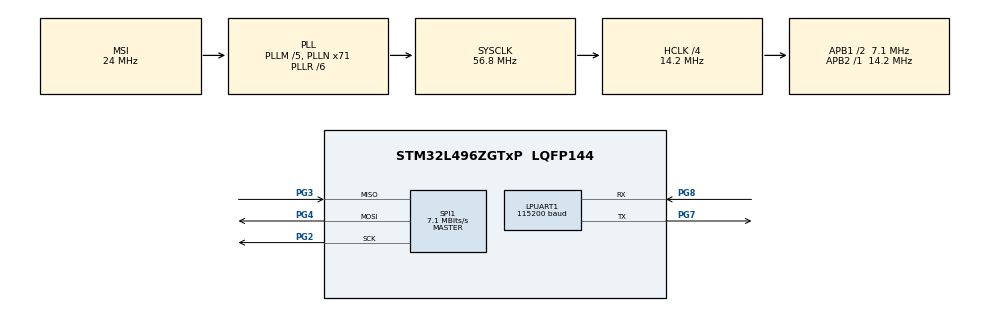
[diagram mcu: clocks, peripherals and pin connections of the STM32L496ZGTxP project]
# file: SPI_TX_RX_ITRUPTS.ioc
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LPUART1.BaudRate=115200
LPUART1.WordLength=UART_WORDLENGTH_8B
Mcu.Family=STM32L4
Mcu.Name=STM32L496ZGTxP
Mcu.Package=LQFP144
NVIC.LPUART1_IRQn=true\:0\:0\:false\:false\:true\:true\:true\:true
NVIC.PriorityGroup=NVIC_PRIORITYGROUP_4
NVIC.SPI1_IRQn=true\:0\:0\:false\:false\:true\:true\:true\:true
PG2.Mode=Full_Duplex_Master
PG2.Signal=SPI1_SCK
PG3.Mode=Full_Duplex_Master
PG3.Signal=SPI1_MISO
PG4.Mode=Full_Duplex_Master
PG4.Signal=SPI1_MOSI
PG7.Mode=Asynchronous
PG7.Signal=LPUART1_TX
PG8.Mode=Asynchronous
PG8.Signal=LPUART1_RX
ProjectManager.HeapSize=0x200
ProjectManager.StackSize=0x400
ProjectManager.TargetToolchain=STM32CubeIDE
RCC.48MHZClocksFreq_Value=24000000
RCC.ADCFreq_Value=48000000
RCC.AHBCLKDivider=RCC_SYSCLK_DIV4
RCC.AHBFreq_Value=14200000
RCC.APB1CLKDivider=RCC_HCLK_DIV2
RCC.APB1Freq_Value=7100000
RCC.APB1TimFreq_Value=14200000
RCC.APB2Freq_Value=14200000
RCC.APB2TimFreq_Value=14200000
RCC.CortexFreq_Value=14200000
RCC.HCLKFreq_Value=14200000
RCC.HSE_VALUE=8000000
RCC.HSI48_VALUE=48000000
RCC.HSI_VALUE=16000000
RCC.LSE_VALUE=32768
RCC.MSIClockRange=RCC_MSIRANGE_9
RCC.MSI_VALUE=24000000
RCC.PLLM=5
RCC.PLLMUL=RCC_PLL_MUL9
RCC.PLLN=71
RCC.PLLR=RCC_PLLR_DIV6
RCC.PLLSAI1N=20
RCC.PRESCALERUSB=RCC_USBCLKSOURCE_PLL_DIV1_5
RCC.SYSCLKFreq_VALUE=56800000
RCC.SYSCLKSource=RCC_SYSCLKSOURCE_PLLCLK
RCC.SYSCLKSourceVirtual=RCC_SYSCLKSOURCE_PLLCLK
RCC.USBFreq_Value=48000000
RCC.VCOOutputFreq_Value=340800000
SPI1.CLKPolarity=SPI_POLARITY_LOW
SPI1.CalculateBaudRate=7.1 MBits/s
SPI1.DataSize=SPI_DATASIZE_8BIT
SPI1.Direction=SPI_DIRECTION_2LINES
SPI1.Mode=SPI_MODE_MASTER
SPI1.VirtualType=VM_MASTER
board=NUCLEO-L496ZG-P

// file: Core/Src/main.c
/* USER CODE BEGIN Header */
/**
  ******************************************************************************
  * @file           : main.c
  * @brief          : Main program body
  ******************************************************************************
  * @attention
  *
  * Copyright (c) 2023 STMicroelectronics.
  * All rights reserved.
  *
  * This software is licensed under terms that can be found in the LICENSE file
  * in the root directory of this software component.
  * If no LICENSE file comes with this software, it is provided AS-IS.
  *
  ******************************************************************************
  */
/* USER CODE END Header */
#include "main.h"

/* USER CODE BEGIN Includes */
#include <stdio.h>
/* USER CODE END Includes */

UART_HandleTypeDef hlpuart1;

SPI_HandleTypeDef hspi1;

void SystemClock_Config(void);
static void MX_GPIO_Init(void);
static void MX_LPUART1_UART_Init(void);
static void MX_SPI1_Init(void);

/* USER CODE BEGIN 0 */
uint8_t tx_data[10]="chirag123";
uint8_t Rx_data[10] = {0};
/* USER CODE END 0 */

int main(void)
{

  /* MCU Configuration--------------------------------------------------------*/

  /* Reset of all peripherals, Initializes the Flash interface and the Systick. */
  HAL_Init();

  /* Configure the system clock */
  SystemClock_Config();

  /* Initialize all configured peripherals */
  MX_GPIO_Init();
  MX_LPUART1_UART_Init();
  MX_SPI1_Init();
  /* USER CODE BEGIN 2 */
  printf("SPI:SIREIAL PERIFRAL INTERFACE\n");
//if(HAL_SPI_TransmitReceive(&hspi1,tx_data,Rx_data,10,1000)==HAL_OK)
//{
//	printf("SPI:SIREIAL PERIFRAL INTERFACE\n");
//	printf("recived data is ==%s\n",Rx_data);
//}
//HAL_SPI_TransmitReceive_IT(&hspi1, tx_data, Rx_data, 10);
if(HAL_SPI_TransmitReceive_IT(&hspi1, tx_data, Rx_data, 10)==HAL_OK)
	{
	printf("intrupt...\n");
	}

  /* USER CODE END 2 */

  /* Infinite loop */
  while (1)
  {

  }
}

void SystemClock_Config(void)
{
  RCC_OscInitTypeDef RCC_OscInitStruct = {0};
  RCC_ClkInitTypeDef RCC_ClkInitStruct = {0};

  /** Configure the main internal regulator output voltage
  */
  if (HAL_PWREx_ControlVoltageScaling(PWR_REGULATOR_VOLTAGE_SCALE1) != HAL_OK)
  {
    Error_Handler();
  }

  /** Initializes the RCC Oscillators according to the specified parameters
  * in the RCC_OscInitTypeDef structure.
  */
  RCC_OscInitStruct.OscillatorType = RCC_OSCILLATORTYPE_MSI;
  RCC_OscInitStruct.MSIState = RCC_MSI_ON;
  RCC_OscInitStruct.MSICalibrationValue = 0;
  RCC_OscInitStruct.MSIClockRange = RCC_MSIRANGE_9;
  RCC_OscInitStruct.PLL.PLLState = RCC_PLL_ON;
  RCC_OscInitStruct.PLL.PLLSource = RCC_PLLSOURCE_MSI;
  RCC_OscInitStruct.PLL.PLLM = 5;
  RCC_OscInitStruct.PLL.PLLN = 71;
  RCC_OscInitStruct.PLL.PLLP = RCC_PLLP_DIV2;
  RCC_OscInitStruct.PLL.PLLQ = RCC_PLLQ_DIV2;
  RCC_OscInitStruct.PLL.PLLR = RCC_PLLR_DIV6;
  if (HAL_RCC_OscConfig(&RCC_OscInitStruct) != HAL_OK)
  {
    Error_Handler();
  }

  /** Initializes the CPU, AHB and APB buses clocks
  */
  RCC_ClkInitStruct.ClockType = RCC_CLOCKTYPE_HCLK|RCC_CLOCKTYPE_SYSCLK
                              |RCC_CLOCKTYPE_PCLK1|RCC_CLOCKTYPE_PCLK2;
  RCC_ClkInitStruct.SYSCLKSource = RCC_SYSCLKSOURCE_PLLCLK;
  RCC_ClkInitStruct.AHBCLKDivider = RCC_SYSCLK_DIV4;
  RCC_ClkInitStruct.APB1CLKDivider = RCC_HCLK_DIV2;
  RCC_ClkInitStruct.APB2CLKDivider = RCC_HCLK_DIV1;

  if (HAL_RCC_ClockConfig(&RCC_ClkInitStruct, FLASH_LATENCY_0) != HAL_OK)
  {
    Error_Handler();
  }
}

static void MX_LPUART1_UART_Init(void)
{

  hlpuart1.Instance = LPUART1;
  hlpuart1.Init.BaudRate = 115200;
  hlpuart1.Init.WordLength = UART_WORDLENGTH_8B;
  hlpuart1.Init.StopBits = UART_STOPBITS_1;
  hlpuart1.Init.Parity = UART_PARITY_NONE;
  hlpuart1.Init.Mode = UART_MODE_TX_RX;
  hlpuart1.Init.HwFlowCtl = UART_HWCONTROL_NONE;
  hlpuart1.Init.OneBitSampling = UART_ONE_BIT_SAMPLE_DISABLE;
  hlpuart1.AdvancedInit.AdvFeatureInit = UART_ADVFEATURE_NO_INIT;
  if (HAL_UART_Init(&hlpuart1) != HAL_OK)
  {
    Error_Handler();
  }

}

static void MX_SPI1_Init(void)
{

  /* SPI1 parameter configuration*/
  hspi1.Instance = SPI1;
  hspi1.Init.Mode = SPI_MODE_MASTER;
  hspi1.Init.Direction = SPI_DIRECTION_2LINES;
  hspi1.Init.DataSize = SPI_DATASIZE_8BIT;
  hspi1.Init.CLKPolarity = SPI_POLARITY_LOW;
  hspi1.Init.CLKPhase = SPI_PHASE_1EDGE;
  hspi1.Init.NSS = SPI_NSS_SOFT;
  hspi1.Init.BaudRatePrescaler = SPI_BAUDRATEPRESCALER_2;
  hspi1.Init.FirstBit = SPI_FIRSTBIT_MSB;
  hspi1.Init.TIMode = SPI_TIMODE_DISABLE;
  hspi1.Init.CRCCalculation = SPI_CRCCALCULATION_DISABLE;
  hspi1.Init.CRCPolynomial = 7;
  hspi1.Init.CRCLength = SPI_CRC_LENGTH_DATASIZE;
  hspi1.Init.NSSPMode = SPI_NSS_PULSE_ENABLE;
  if (HAL_SPI_Init(&hspi1) != HAL_OK)
  {
    Error_Handler();
  }

}

static void MX_GPIO_Init(void)
{

  /* GPIO Ports Clock Enable */
  __HAL_RCC_GPIOG_CLK_ENABLE();
  HAL_PWREx_EnableVddIO2();

}

void Error_Handler(void)
{
  __disable_irq();
  while (1)
  {
  }
}
